# CY8C5888LTI_LP097 register map
File version: 0.1
Registers are 8-bit, read-write, no defined reset value unless marked. A register's access mark holds for its fields unless they carry their own. Offsets are from the block's base; [hi:lo] are bit positions; {n}, {i} and the like mark numbered series.

## Maximum_Peak_Detector_A_Sample_Hold
Base 0x00000000
0x400043A9 Maximum_Peak_Detector_A_Sample_Hold_Active_Power_Manager_Register — SC Active Power Manager Register
  [3:0] en_swcap — Enable switchcap block(s). Populated subsystems are counted from the LSB, for example bit 0 corresponds to switchcap block 0.
0x400043B9 Maximum_Peak_Detector_A_Sample_Hold_Standby_Power_Manager_Register — SC StandBy power Manager Register
  [3:0] en_swcap — Enable switchcap block(s) during the standby Power mode. Populated subsystems are counted from the LSB, for example bit 0 corresponds to switchcap block 0.
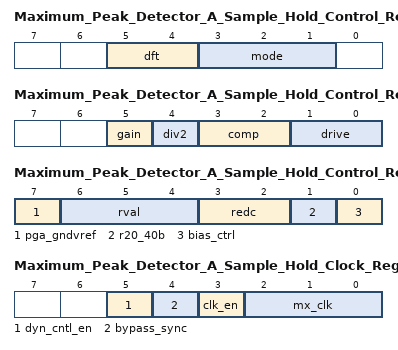
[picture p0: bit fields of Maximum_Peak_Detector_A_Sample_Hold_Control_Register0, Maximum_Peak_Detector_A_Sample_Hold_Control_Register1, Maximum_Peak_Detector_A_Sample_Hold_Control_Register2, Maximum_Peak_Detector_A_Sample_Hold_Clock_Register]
0x40005804 Maximum_Peak_Detector_A_Sample_Hold_Control_Register0 — SC_CR0 Register
  [5:4] dft — Enable DFT mode for switch cap block
    0=SC_DFT_NORMAL (Normal Operation); 1=SC_DFT_VBOOST (Vboost DFT); 2=SC_DFT_MODE_DEPENDENT (Mode Dependent (PGA Mode = Voltage Integrator, TIA Mode = Charge Integrator, Naked Opamp Mode = Comparator)); 3=SC_DFT_RESET (DFT Rreset)
  [3:1] mode ro — Configuration selection for SC block
    0=SC_MODE_NAKED_OPAMP (Naked Op-Amp); 1=SC_MODE_TIA (Transimpedance Amplifier (TIA)); 2=SC_MODE_CTMIXER (Continuous Time Mixer); 3=SC_MODE_NRZ_SH (Discrete Time Mixer - NRZ S/H); 4=SC_MODE_UNITY (Unity Gain Buffer); 5=SC_MODE_1ST_MOD (First Order Modulator); 6=SC_MODE_PGA (Programmable Gain Amplifier (PGA)); 7=SC_MODE_TRACKANDHOLD (Track and Hold)
0x40005805 Maximum_Peak_Detector_A_Sample_Hold_Control_Register1 — SC_CR1 Register
  [5] gain — Controls the ratio of the feedback cap for S/H Mixer mode and PGA mode
    0=GAIN_0DB (0 dB); 1=GAIN_6DB (6 dB)
  [4] div2 — When 0, the sample clock only needs to be half the desired sample frequency for S/H Mixer mode
    0=SC_DIV2_DISABLE (no frequency division); 1=SC_DIV2_ENABLE (SC CLK is divided by two)
  [3:2] comp — Selects between various compensation capacitor sizes
    0=SC_COMP_3P0PF (3.0pF); 1=SC_COMP_3P6PF (3.6pF); 2=SC_COMP_4P35PF (4.35pF); 3=SC_COMP_5P1PF (5.1pF)
  [1:0] drive — Selects between current settings (I_Load (uA)) in the output buffer
    0=I_LOAD_175UA (175 uA); 1=I_LOAD_260UA (260 uA); 2=I_LOAD_330UA (330 uA); 3=I_LOAD_400UA (400 uA)
0x40005806 Maximum_Peak_Detector_A_Sample_Hold_Control_Register2 — SC_CR2 Register
  [7] pga_gndvref — Programmable Gain Amplifier Application - Ground VREF
    0=SC_PGA_GNDVREF_DIS (VREF not grounded); 1=SC_PGA_GNDVREF_EN (VREF grounded)
  [6:4] rval — Programmable Gain Amplifier (PGA) and Transimpedance Amplifier (TIA): Feedback resistor (Rfb)
    0=SC_RVAL_20 (20 kOhm); 1=SC_RVAL_30 (30 kOhm); 2=SC_RVAL_40 (40 kOhm); 3=SC_RVAL_80 (80 kOhm); 4=SC_RVAL_120 (120 kOhm); 5=SC_RVAL_250 (250 kOhm); 6=SC_RVAL_500 (500 kOhm); 7=SC_RVAL_1000 (1 MegaOhm)
  [3:2] redc — Stability control setting. Adjusts capactiance between amplifier output and first stage
    0=SC_REDC_00 (Varies depending on mode. See Switched Cap documentation); 1=SC_REDC_01 (Varies depending on mode. See Switched Cap documentation); 2=SC_REDC_10 (Varies depending on mode. See Switched Cap documentation); 3=SC_REDC_11 (Varies depending on mode. See Switched Cap documentation)
  [1] r20_40b — PGA Mode: input impedance (Rin), Mixer Mode: input and feedback impedance (Rmix)
    0=SC_R20_40B_40K (40kOhm); 1=SC_R20_40B_20K (20kOhm)
  [0] bias_ctrl — Toggles the bias current in the amplifier between normal and 1/2
    0=BIAS_1X (1x current reference reduces bandwidth to increase stability); 1=BIAS_2X (normal operation - 2x current reference to increase bandwidth)
0x40005A1B Maximum_Peak_Detector_A_Sample_Hold_Clock_Register — SC_CLK Register
  [5] dyn_cntl_en — Enable Dynamic Control (UDB generated clock source drives dynamic control)
    0=DYN_CNTL_DIS (Dynamic Control Disabled); 1=DYN_CNTL_EN (Dynamic Control Enabled)
  [4] bypass_sync — Bypass Synchronization
    0=Synchronization not bypassed (Synchronization enabled); 1=Synchronization bypassed (Synchronization disabled)
  [3] clk_en — Clock gating control
    0=disable clock; 1=enable clock
  [2:0] mx_clk — Clock Selection
    {v}=Select clk_a{v} and clk_a{v}_dig (v=0..3); 4=Select UDB generated clock
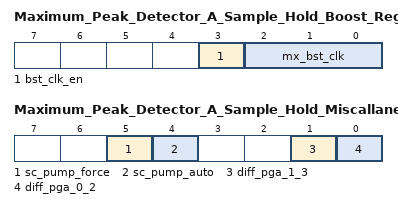
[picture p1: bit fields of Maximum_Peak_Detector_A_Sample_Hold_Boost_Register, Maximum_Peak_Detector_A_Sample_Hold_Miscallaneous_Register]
0x40005A1C Maximum_Peak_Detector_A_Sample_Hold_Boost_Register — SC__BST Register
  [3] bst_clk_en — Clock gating control
    0=CLK_EN_0 (disable clock); 1=CLK_EN_1 (enable clock)
  [2:0] mx_bst_clk — Clock Selection
    {v}=MX_CLK_{v} (Select clk_a{v} and clk_a{v}_dig) (v=0..3); 4=MX_CLK_4 (Select UDB generated clock); 5=MX_CLK_5 (Reserved); 6=MX_CLK_6 (Reserved); 7=MX_CLK_7 (Reserved)
0x40005B56 Maximum_Peak_Detector_A_Sample_Hold_Miscallaneous_Register — SC_MISC Register
  [5] sc_pump_force — force pumping - if block enabled enable pump regardless of voltage state
    0=Disable_Force_Pumping (Force Pumping Disabled); 1=Enable_Force_Pumping (Force pumping Enabled)
  [4] sc_pump_auto — enable autopumping - if block enabled pump when low voltage detected
    0=Disable_Auto_Pumping (Auto pumping disabled); 1=Enable_Auto_Pumping (Auto pumping enabled)
  [1] diff_pga_1_3 — Switched Cap Pair Connect for Differential Amplifier Applications
    0=SC_DIFF_PGA_DISABLED (Differential PGA pair 1_3 connect disabled); 1=SC_DIFF_PGA_ENABLED (Differential PGA pair 1_3 connect enabled)
  [0] diff_pga_0_2 — Switched Cap Pair Connect for Differential Amplifier Applications
    0=SC_DIFF_PGA_DISABLED (Differential PGA pair 0_2 connect disabled); 1=SC_DIFF_PGA_ENABLED (Differential PGA pair 0_2 connect Enabled)
